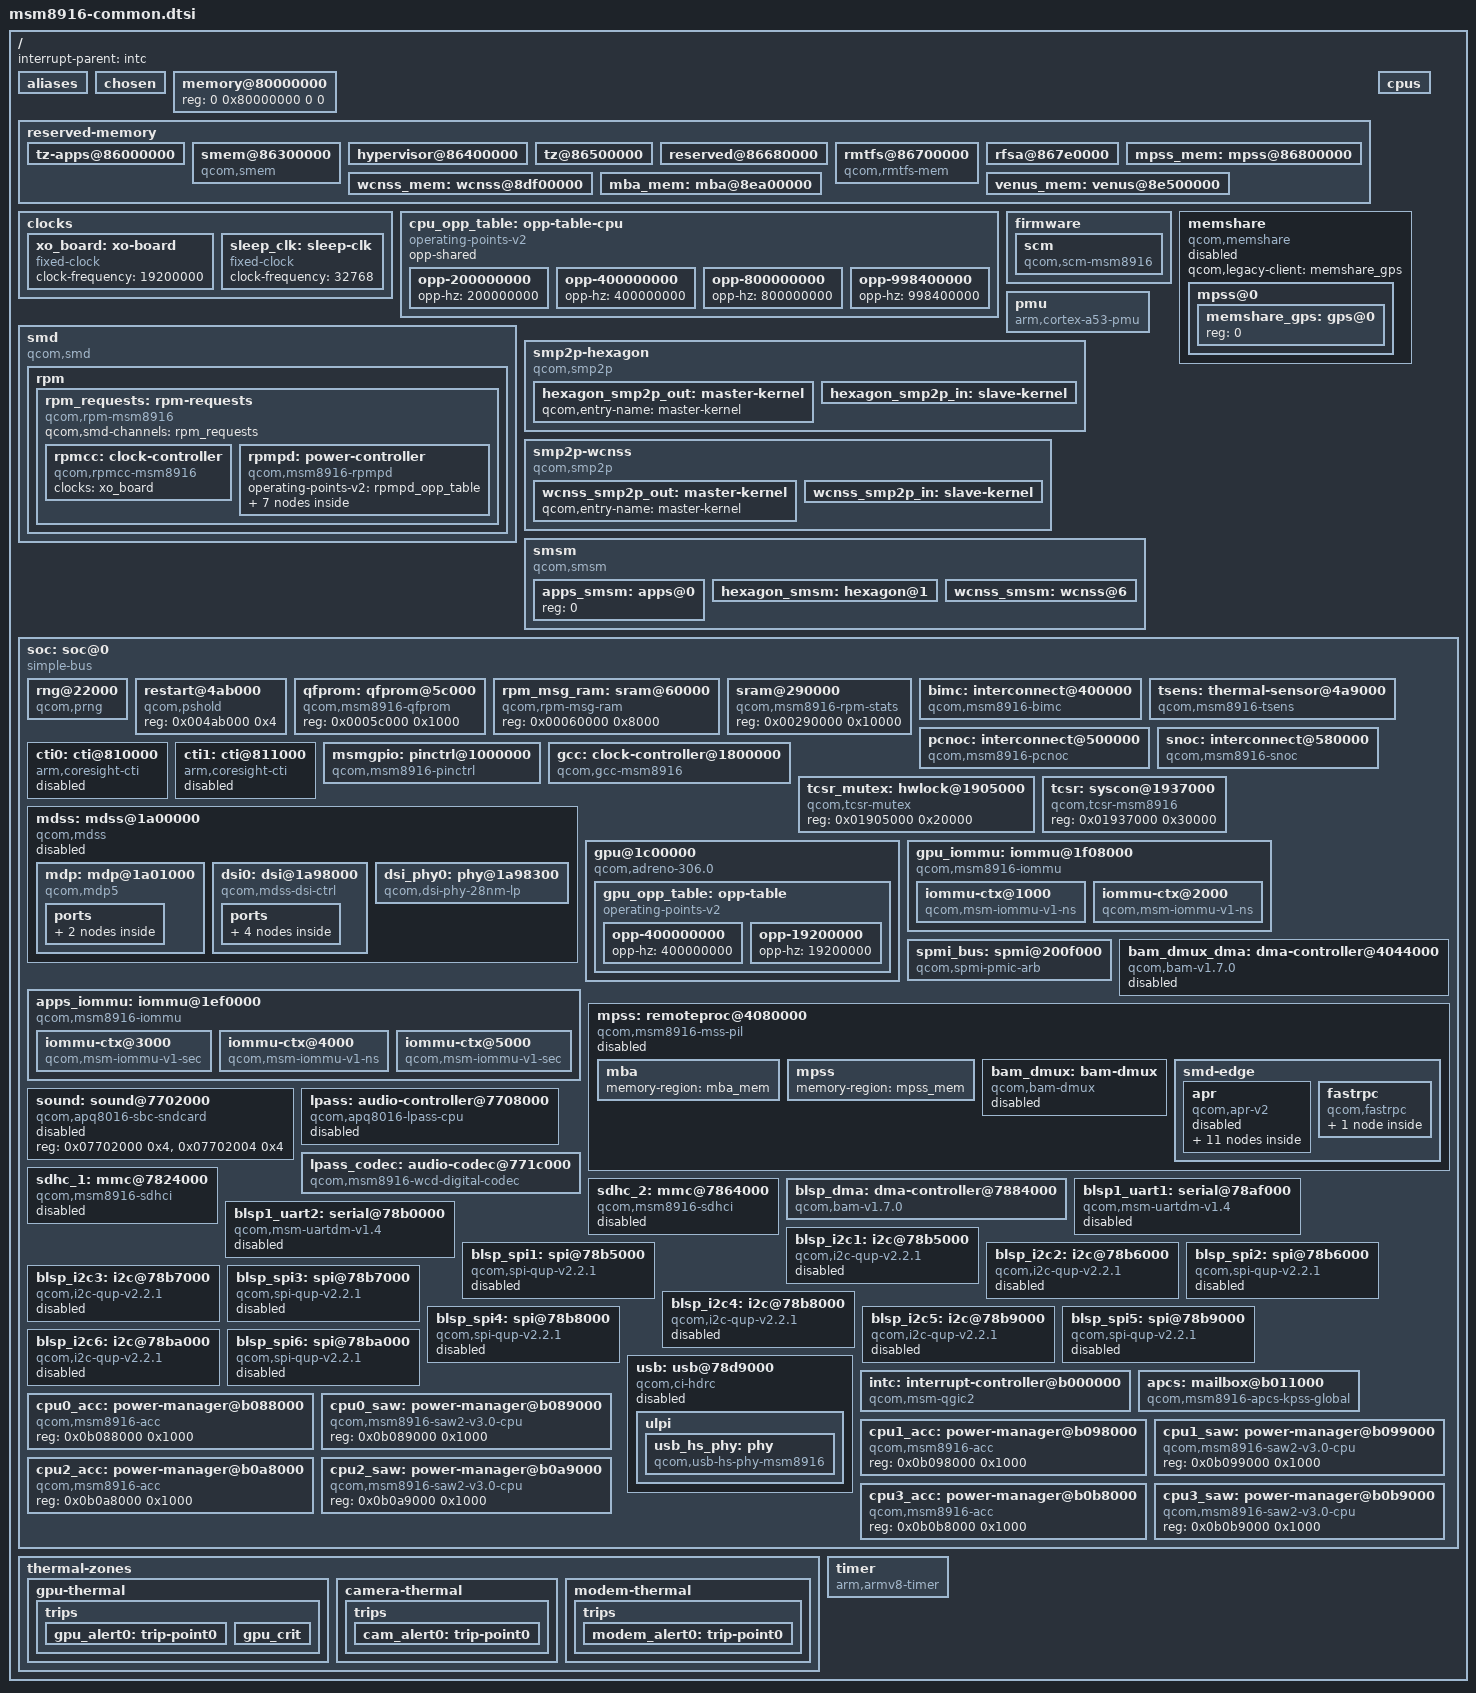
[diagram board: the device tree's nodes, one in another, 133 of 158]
// SPDX-License-Identifier: GPL-2.0-only
/*
 * Copyright (c) 2013-2015, The Linux Foundation. All rights reserved.
 */

#include <dt-bindings/clock/qcom,rpmcc.h>
#include <dt-bindings/interrupt-controller/arm-gic.h>
#include <dt-bindings/power/qcom-rpmpd.h>
#include <dt-bindings/soc/qcom,apr.h>
#include <dt-bindings/soc/qcom,memshare.h>
#include <dt-bindings/thermal/thermal.h>

/ {
	interrupt-parent = <&intc>;

	#address-cells = <2>;
	#size-cells = <2>;

	aliases {
		mmc0 = &sdhc_1; /* SDC1 eMMC slot */
		mmc1 = &sdhc_2; /* SDC2 SD card slot */
	};

	chosen { };

	memory@80000000 {
		device_type = "memory";
		/* We expect the bootloader to fill in the reg */
		reg = <0 0x80000000 0 0>;
	};

	reserved-memory {
		#address-cells = <2>;
		#size-cells = <2>;
		ranges;

		tz-apps@86000000 {
			reg = <0x0 0x86000000 0x0 0x300000>;
			no-map;
		};

		smem@86300000 {
			compatible = "qcom,smem";
			reg = <0x0 0x86300000 0x0 0x100000>;
			no-map;

			hwlocks = <&tcsr_mutex 3>;
			qcom,rpm-msg-ram = <&rpm_msg_ram>;
		};

		hypervisor@86400000 {
			reg = <0x0 0x86400000 0x0 0x100000>;
			no-map;
		};

		tz@86500000 {
			reg = <0x0 0x86500000 0x0 0x180000>;
			no-map;
		};

		reserved@86680000 {
			reg = <0x0 0x86680000 0x0 0x80000>;
			no-map;
		};

		rmtfs@86700000 {
			compatible = "qcom,rmtfs-mem";
			reg = <0x0 0x86700000 0x0 0xe0000>;
			no-map;

			qcom,client-id = <1>;
		};

		rfsa@867e0000 {
			reg = <0x0 0x867e0000 0x0 0x20000>;
			no-map;
		};

		mpss_mem: mpss@86800000 {
			reg = <0x0 0x86800000 0x0 0x2b00000>;
			no-map;
		};

		wcnss_mem: wcnss@8df00000 {
			reg = <0x0 0x8df00000 0x0 0x600000>;
			no-map;
		};

		venus_mem: venus@8e500000 {
			reg = <0x0 0x8e500000 0x0 0x500000>;
			no-map;
		};

		mba_mem: mba@8ea00000 {
			reg = <0x0 0x8ea00000 0x0 0x100000>;
			no-map;
		};
	};

	clocks {
		xo_board: xo-board {
			compatible = "fixed-clock";
			#clock-cells = <0>;
			clock-frequency = <19200000>;
		};

		sleep_clk: sleep-clk {
			compatible = "fixed-clock";
			#clock-cells = <0>;
			clock-frequency = <32768>;
		};
	};

	cpus { };

	cpu_opp_table: opp-table-cpu {
		compatible = "operating-points-v2";
		opp-shared;

		opp-200000000 {
			opp-hz = /bits/ 64 <200000000>;
		};
		opp-400000000 {
			opp-hz = /bits/ 64 <400000000>;
		};
		opp-800000000 {
			opp-hz = /bits/ 64 <800000000>;
		};
		opp-998400000 {
			opp-hz = /bits/ 64 <998400000>;
		};
	};

	firmware {
		scm: scm {
			compatible = "qcom,scm-msm8916", "qcom,scm";
			clocks = <&gcc GCC_CRYPTO_CLK>,
				 <&gcc GCC_CRYPTO_AXI_CLK>,
				 <&gcc GCC_CRYPTO_AHB_CLK>;
			clock-names = "core", "bus", "iface";
			#reset-cells = <1>;

			qcom,dload-mode = <&tcsr 0x6100>;
		};
	};

	memshare: memshare {
		compatible = "qcom,memshare";
		qcom,legacy-client = <&memshare_gps>;

		status = "disabled";

		#address-cells = <1>;
		#size-cells = <0>;

		mpss@0 {
			reg = <MEMSHARE_PROC_MPSS_V01>;
			qcom,qrtr-node = <0>;

			#address-cells = <1>;
			#size-cells = <0>;

			memshare_gps: gps@0 {
				reg = <0>;
			};
		};
	};

	pmu {
		compatible = "arm,cortex-a53-pmu";
		interrupts = <GIC_PPI 7 (GIC_CPU_MASK_SIMPLE(4) | IRQ_TYPE_LEVEL_HIGH)>;
	};

	smd {
		compatible = "qcom,smd";

		rpm {
			interrupts = <GIC_SPI 168 IRQ_TYPE_EDGE_RISING>;
			qcom,ipc = <&apcs 8 0>;
			qcom,smd-edge = <15>;

			rpm_requests: rpm-requests {
				compatible = "qcom,rpm-msm8916";
				qcom,smd-channels = "rpm_requests";

				rpmcc: clock-controller {
					compatible = "qcom,rpmcc-msm8916", "qcom,rpmcc";
					#clock-cells = <1>;
					clocks = <&xo_board>;
					clock-names = "xo";
				};

				rpmpd: power-controller {
					compatible = "qcom,msm8916-rpmpd";
					#power-domain-cells = <1>;
					operating-points-v2 = <&rpmpd_opp_table>;

					rpmpd_opp_table: opp-table {
						compatible = "operating-points-v2";

						rpmpd_opp_ret: opp1 {
							opp-level = <1>;
						};
						rpmpd_opp_svs_krait: opp2 {
							opp-level = <2>;
						};
						rpmpd_opp_svs_soc: opp3 {
							opp-level = <3>;
						};
						rpmpd_opp_nom: opp4 {
							opp-level = <4>;
						};
						rpmpd_opp_turbo: opp5 {
							opp-level = <5>;
						};
						rpmpd_opp_super_turbo: opp6 {
							opp-level = <6>;
						};
					};
				};
			};
		};
	};

	smp2p-hexagon {
		compatible = "qcom,smp2p";
		qcom,smem = <435>, <428>;

		interrupts = <GIC_SPI 27 IRQ_TYPE_EDGE_RISING>;

		qcom,ipc = <&apcs 8 14>;

		qcom,local-pid = <0>;
		qcom,remote-pid = <1>;

		hexagon_smp2p_out: master-kernel {
			qcom,entry-name = "master-kernel";

			#qcom,smem-state-cells = <1>;
		};

		hexagon_smp2p_in: slave-kernel {
			qcom,entry-name = "slave-kernel";

			interrupt-controller;
			#interrupt-cells = <2>;
		};
	};

	smp2p-wcnss {
		compatible = "qcom,smp2p";
		qcom,smem = <451>, <431>;

		interrupts = <GIC_SPI 143 IRQ_TYPE_EDGE_RISING>;

		qcom,ipc = <&apcs 8 18>;

		qcom,local-pid = <0>;
		qcom,remote-pid = <4>;

		wcnss_smp2p_out: master-kernel {
			qcom,entry-name = "master-kernel";

			#qcom,smem-state-cells = <1>;
		};

		wcnss_smp2p_in: slave-kernel {
			qcom,entry-name = "slave-kernel";

			interrupt-controller;
			#interrupt-cells = <2>;
		};
	};

	smsm {
		compatible = "qcom,smsm";

		#address-cells = <1>;
		#size-cells = <0>;

		qcom,ipc-1 = <&apcs 8 13>;
		qcom,ipc-3 = <&apcs 8 19>;

		apps_smsm: apps@0 {
			reg = <0>;

			#qcom,smem-state-cells = <1>;
		};

		hexagon_smsm: hexagon@1 {
			reg = <1>;
			interrupts = <GIC_SPI 26 IRQ_TYPE_EDGE_RISING>;

			interrupt-controller;
			#interrupt-cells = <2>;
		};

		wcnss_smsm: wcnss@6 {
			reg = <6>;
			interrupts = <GIC_SPI 144 IRQ_TYPE_EDGE_RISING>;

			interrupt-controller;
			#interrupt-cells = <2>;
		};
	};

	soc: soc@0 {
		#address-cells = <1>;
		#size-cells = <1>;
		ranges = <0 0 0 0xffffffff>;
		compatible = "simple-bus";

		rng@22000 {
			compatible = "qcom,prng";
			reg = <0x00022000 0x200>;
			clocks = <&gcc GCC_PRNG_AHB_CLK>;
			clock-names = "core";
		};

		restart@4ab000 {
			compatible = "qcom,pshold";
			reg = <0x004ab000 0x4>;
		};

		qfprom: qfprom@5c000 {
			compatible = "qcom,msm8916-qfprom", "qcom,qfprom";
			reg = <0x0005c000 0x1000>;
			#address-cells = <1>;
			#size-cells = <1>;
		};

		rpm_msg_ram: sram@60000 {
			compatible = "qcom,rpm-msg-ram";
			reg = <0x00060000 0x8000>;
		};

		sram@290000 {
			compatible = "qcom,msm8916-rpm-stats";
			reg = <0x00290000 0x10000>;
		};

		bimc: interconnect@400000 {
			compatible = "qcom,msm8916-bimc";
			reg = <0x00400000 0x62000>;
			#interconnect-cells = <1>;
			clock-names = "bus", "bus_a";
			clocks = <&rpmcc RPM_SMD_BIMC_CLK>,
				 <&rpmcc RPM_SMD_BIMC_A_CLK>;
		};

		tsens: thermal-sensor@4a9000 {
			compatible = "qcom,msm8916-tsens", "qcom,tsens-v0_1";
			reg = <0x004a9000 0x1000>, /* TM */
			      <0x004a8000 0x1000>; /* SROT */
			nvmem-cells = <&tsens_caldata>, <&tsens_calsel>;
			nvmem-cell-names = "calib", "calib_sel";
			#qcom,sensors = <5>;
			interrupts = <GIC_SPI 184 IRQ_TYPE_LEVEL_HIGH>;
			interrupt-names = "uplow";
			#thermal-sensor-cells = <1>;
		};

		pcnoc: interconnect@500000 {
			compatible = "qcom,msm8916-pcnoc";
			reg = <0x00500000 0x11000>;
			#interconnect-cells = <1>;
			clock-names = "bus", "bus_a";
			clocks = <&rpmcc RPM_SMD_PCNOC_CLK>,
				 <&rpmcc RPM_SMD_PCNOC_A_CLK>;
		};

		snoc: interconnect@580000 {
			compatible = "qcom,msm8916-snoc";
			reg = <0x00580000 0x14000>;
			#interconnect-cells = <1>;
			clock-names = "bus", "bus_a";
			clocks = <&rpmcc RPM_SMD_SNOC_CLK>,
				 <&rpmcc RPM_SMD_SNOC_A_CLK>;
		};

		/* System CTIs */
		/* CTI 0 - TMC connections */
		cti0: cti@810000 {
			compatible = "arm,coresight-cti", "arm,primecell";
			reg = <0x00810000 0x1000>;

			clocks = <&rpmcc RPM_QDSS_CLK>;
			clock-names = "apb_pclk";

			status = "disabled";
		};

		/* CTI 1 - TPIU connections */
		cti1: cti@811000 {
			compatible = "arm,coresight-cti", "arm,primecell";
			reg = <0x00811000 0x1000>;

			clocks = <&rpmcc RPM_QDSS_CLK>;
			clock-names = "apb_pclk";

			status = "disabled";
		};

		msmgpio: pinctrl@1000000 {
			compatible = "qcom,msm8916-pinctrl";
			reg = <0x01000000 0x300000>;
			interrupts = <GIC_SPI 208 IRQ_TYPE_LEVEL_HIGH>;
			gpio-controller;
			gpio-ranges = <&msmgpio 0 0 122>;
			#gpio-cells = <2>;
			interrupt-controller;
			#interrupt-cells = <2>;
		};

		gcc: clock-controller@1800000 {
			compatible = "qcom,gcc-msm8916";
			#clock-cells = <1>;
			#reset-cells = <1>;
			#power-domain-cells = <1>;
			reg = <0x01800000 0x80000>;
			clocks = <&xo_board>,
				 <&sleep_clk>,
				 <&dsi_phy0 1>,
				 <&dsi_phy0 0>,
				 <0>,
				 <0>,
				 <0>;
			clock-names = "xo",
				      "sleep_clk",
				      "dsi0pll",
				      "dsi0pllbyte",
				      "ext_mclk",
				      "ext_pri_i2s",
				      "ext_sec_i2s";
		};

		tcsr_mutex: hwlock@1905000 {
			compatible = "qcom,tcsr-mutex";
			reg = <0x01905000 0x20000>;
			#hwlock-cells = <1>;
		};

		tcsr: syscon@1937000 {
			compatible = "qcom,tcsr-msm8916", "syscon";
			reg = <0x01937000 0x30000>;
		};

		mdss: mdss@1a00000 {
			status = "disabled";
			compatible = "qcom,mdss";
			reg = <0x01a00000 0x1000>,
			      <0x01ac8000 0x3000>;
			reg-names = "mdss_phys", "vbif_phys";

			power-domains = <&gcc MDSS_GDSC>;

			clocks = <&gcc GCC_MDSS_AHB_CLK>,
				 <&gcc GCC_MDSS_AXI_CLK>,
				 <&gcc GCC_MDSS_VSYNC_CLK>;
			clock-names = "iface",
				      "bus",
				      "vsync";

			interrupts = <GIC_SPI 72 IRQ_TYPE_LEVEL_HIGH>;

			interrupt-controller;
			#interrupt-cells = <1>;

			#address-cells = <1>;
			#size-cells = <1>;
			ranges;

			mdp: mdp@1a01000 {
				compatible = "qcom,mdp5";
				reg = <0x01a01000 0x89000>;
				reg-names = "mdp_phys";

				interrupt-parent = <&mdss>;
				interrupts = <0>;

				clocks = <&gcc GCC_MDSS_AHB_CLK>,
					 <&gcc GCC_MDSS_AXI_CLK>,
					 <&gcc GCC_MDSS_MDP_CLK>,
					 <&gcc GCC_MDSS_VSYNC_CLK>;
				clock-names = "iface",
					      "bus",
					      "core",
					      "vsync";

				iommus = <&apps_iommu 4>;

				ports {
					#address-cells = <1>;
					#size-cells = <0>;

					port@0 {
						reg = <0>;
						mdp5_intf1_out: endpoint {
							remote-endpoint = <&dsi0_in>;
						};
					};
				};
			};

			dsi0: dsi@1a98000 {
				compatible = "qcom,mdss-dsi-ctrl";
				reg = <0x01a98000 0x25c>;
				reg-names = "dsi_ctrl";

				interrupt-parent = <&mdss>;
				interrupts = <4>;

				assigned-clocks = <&gcc BYTE0_CLK_SRC>,
						  <&gcc PCLK0_CLK_SRC>;
				assigned-clock-parents = <&dsi_phy0 0>,
							 <&dsi_phy0 1>;

				clocks = <&gcc GCC_MDSS_MDP_CLK>,
					 <&gcc GCC_MDSS_AHB_CLK>,
					 <&gcc GCC_MDSS_AXI_CLK>,
					 <&gcc GCC_MDSS_BYTE0_CLK>,
					 <&gcc GCC_MDSS_PCLK0_CLK>,
					 <&gcc GCC_MDSS_ESC0_CLK>;
				clock-names = "mdp_core",
					      "iface",
					      "bus",
					      "byte",
					      "pixel",
					      "core";
				phys = <&dsi_phy0>;

				#address-cells = <1>;
				#size-cells = <0>;

				ports {
					#address-cells = <1>;
					#size-cells = <0>;

					port@0 {
						reg = <0>;
						dsi0_in: endpoint {
							remote-endpoint = <&mdp5_intf1_out>;
						};
					};

					port@1 {
						reg = <1>;
						dsi0_out: endpoint {
						};
					};
				};
			};

			dsi_phy0: phy@1a98300 {
				compatible = "qcom,dsi-phy-28nm-lp";
				reg = <0x01a98300 0xd4>,
				      <0x01a98500 0x280>,
				      <0x01a98780 0x30>;
				reg-names = "dsi_pll",
					    "dsi_phy",
					    "dsi_phy_regulator";

				#clock-cells = <1>;
				#phy-cells = <0>;

				clocks = <&gcc GCC_MDSS_AHB_CLK>,
					 <&xo_board>;
				clock-names = "iface", "ref";
			};
		};

		gpu@1c00000 {
			compatible = "qcom,adreno-306.0", "qcom,adreno";
			reg = <0x01c00000 0x20000>;
			reg-names = "kgsl_3d0_reg_memory";
			interrupts = <GIC_SPI 33 IRQ_TYPE_LEVEL_HIGH>;
			interrupt-names = "kgsl_3d0_irq";
			clock-names =
			    "core",
			    "iface",
			    "mem",
			    "mem_iface",
			    "alt_mem_iface",
			    "gfx3d";
			clocks =
			    <&gcc GCC_OXILI_GFX3D_CLK>,
			    <&gcc GCC_OXILI_AHB_CLK>,
			    <&gcc GCC_OXILI_GMEM_CLK>,
			    <&gcc GCC_BIMC_GFX_CLK>,
			    <&gcc GCC_BIMC_GPU_CLK>,
			    <&gcc GFX3D_CLK_SRC>;
			power-domains = <&gcc OXILI_GDSC>;
			operating-points-v2 = <&gpu_opp_table>;
			iommus = <&gpu_iommu 1>, <&gpu_iommu 2>;

			gpu_opp_table: opp-table {
				compatible = "operating-points-v2";

				opp-400000000 {
					opp-hz = /bits/ 64 <400000000>;
				};
				opp-19200000 {
					opp-hz = /bits/ 64 <19200000>;
				};
			};
		};

		apps_iommu: iommu@1ef0000 {
			#address-cells = <1>;
			#size-cells = <1>;
			#iommu-cells = <1>;
			compatible = "qcom,msm8916-iommu", "qcom,msm-iommu-v1";
			ranges = <0 0x01e20000 0x40000>;
			reg = <0x01ef0000 0x3000>;
			clocks = <&gcc GCC_SMMU_CFG_CLK>,
				 <&gcc GCC_APSS_TCU_CLK>;
			clock-names = "iface", "bus";
			qcom,iommu-secure-id = <17>;

			/* VFE */
			iommu-ctx@3000 {
				compatible = "qcom,msm-iommu-v1-sec";
				reg = <0x3000 0x1000>;
				interrupts = <GIC_SPI 70 IRQ_TYPE_LEVEL_HIGH>;
			};

			/* MDP_0 */
			iommu-ctx@4000 {
				compatible = "qcom,msm-iommu-v1-ns";
				reg = <0x4000 0x1000>;
				interrupts = <GIC_SPI 70 IRQ_TYPE_LEVEL_HIGH>;
			};

			/* VENUS_NS */
			iommu-ctx@5000 {
				compatible = "qcom,msm-iommu-v1-sec";
				reg = <0x5000 0x1000>;
				interrupts = <GIC_SPI 70 IRQ_TYPE_LEVEL_HIGH>;
			};
		};

		gpu_iommu: iommu@1f08000 {
			#address-cells = <1>;
			#size-cells = <1>;
			#iommu-cells = <1>;
			compatible = "qcom,msm8916-iommu", "qcom,msm-iommu-v1";
			ranges = <0 0x01f08000 0x10000>;
			clocks = <&gcc GCC_SMMU_CFG_CLK>,
				 <&gcc GCC_GFX_TCU_CLK>;
			clock-names = "iface", "bus";
			qcom,iommu-secure-id = <18>;

			/* GFX3D_USER */
			iommu-ctx@1000 {
				compatible = "qcom,msm-iommu-v1-ns";
				reg = <0x1000 0x1000>;
				interrupts = <GIC_SPI 241 IRQ_TYPE_LEVEL_HIGH>;
			};

			/* GFX3D_PRIV */
			iommu-ctx@2000 {
				compatible = "qcom,msm-iommu-v1-ns";
				reg = <0x2000 0x1000>;
				interrupts = <GIC_SPI 242 IRQ_TYPE_LEVEL_HIGH>;
			};
		};

		spmi_bus: spmi@200f000 {
			compatible = "qcom,spmi-pmic-arb";
			reg = <0x0200f000 0x001000>,
			      <0x02400000 0x400000>,
			      <0x02c00000 0x400000>,
			      <0x03800000 0x200000>,
			      <0x0200a000 0x002100>;
			reg-names = "core", "chnls", "obsrvr", "intr", "cnfg";
			interrupt-names = "periph_irq";
			interrupts = <GIC_SPI 190 IRQ_TYPE_LEVEL_HIGH>;
			qcom,ee = <0>;
			qcom,channel = <0>;
			#address-cells = <2>;
			#size-cells = <0>;
			interrupt-controller;
			#interrupt-cells = <4>;
		};

		bam_dmux_dma: dma-controller@4044000 {
			compatible = "qcom,bam-v1.7.0";
			reg = <0x04044000 0x19000>;
			interrupts = <GIC_SPI 29 IRQ_TYPE_LEVEL_HIGH>;
			#dma-cells = <1>;
			qcom,ee = <0>;

			num-channels = <6>;
			qcom,num-ees = <1>;
			qcom,powered-remotely;

			status = "disabled";
		};

		mpss: remoteproc@4080000 {
			compatible = "qcom,msm8916-mss-pil";
			reg = <0x04080000 0x100>,
			      <0x04020000 0x040>;

			reg-names = "qdsp6", "rmb";

			interrupts-extended = <&intc GIC_SPI 24 IRQ_TYPE_EDGE_RISING>,
					      <&hexagon_smp2p_in 0 IRQ_TYPE_EDGE_RISING>,
					      <&hexagon_smp2p_in 1 IRQ_TYPE_EDGE_RISING>,
					      <&hexagon_smp2p_in 2 IRQ_TYPE_EDGE_RISING>,
					      <&hexagon_smp2p_in 3 IRQ_TYPE_EDGE_RISING>;
			interrupt-names = "wdog", "fatal", "ready",
					  "handover", "stop-ack";

			power-domains = <&rpmpd MSM8916_VDDCX>,
					<&rpmpd MSM8916_VDDMX>;
			power-domain-names = "cx", "mx";

			clocks = <&gcc GCC_MSS_CFG_AHB_CLK>,
				 <&gcc GCC_MSS_Q6_BIMC_AXI_CLK>,
				 <&gcc GCC_BOOT_ROM_AHB_CLK>,
				 <&xo_board>;
			clock-names = "iface", "bus", "mem", "xo";

			qcom,smem-states = <&hexagon_smp2p_out 0>;
			qcom,smem-state-names = "stop";

			resets = <&scm 0>;
			reset-names = "mss_restart";

			qcom,halt-regs = <&tcsr 0x18000 0x19000 0x1a000>;

			status = "disabled";

			mba {
				memory-region = <&mba_mem>;
			};

			mpss {
				memory-region = <&mpss_mem>;
			};

			bam_dmux: bam-dmux {
				compatible = "qcom,bam-dmux";

				interrupt-parent = <&hexagon_smsm>;
				interrupts = <1 IRQ_TYPE_EDGE_BOTH>, <11 IRQ_TYPE_EDGE_BOTH>;
				interrupt-names = "pc", "pc-ack";

				qcom,smem-states = <&apps_smsm 1>, <&apps_smsm 11>;
				qcom,smem-state-names = "pc", "pc-ack";

				dmas = <&bam_dmux_dma 4>, <&bam_dmux_dma 5>;
				dma-names = "tx", "rx";

				status = "disabled";
			};

			smd-edge {
				interrupts = <GIC_SPI 25 IRQ_TYPE_EDGE_RISING>;

				qcom,smd-edge = <0>;
				qcom,ipc = <&apcs 8 12>;
				qcom,remote-pid = <1>;

				label = "hexagon";

				apr: apr {
					compatible = "qcom,apr-v2";
					qcom,smd-channels = "apr_audio_svc";
					qcom,apr-domain = <APR_DOMAIN_ADSP>;
					#address-cells = <1>;
					#size-cells = <0>;
					status = "disabled";

					apr-service@3 {
						reg = <APR_SVC_ADSP_CORE>;
						compatible = "qcom,q6core";
					};

					q6afe: apr-service@4 {
						compatible = "qcom,q6afe";
						reg = <APR_SVC_AFE>;
						q6afedai: dais {
							compatible = "qcom,q6afe-dais";
							#address-cells = <1>;
							#size-cells = <0>;
							#sound-dai-cells = <1>;
						};
					};

					q6asm: apr-service@7 {
						compatible = "qcom,q6asm";
						reg = <APR_SVC_ASM>;
						q6asmdai: dais {
							compatible = "qcom,q6asm-dais";
							#address-cells = <1>;
							#size-cells = <0>;
							#sound-dai-cells = <1>;
						};
					};

					q6adm: apr-service@8 {
						compatible = "qcom,q6adm";
						reg = <APR_SVC_ADM>;
						q6routing: routing {
							compatible = "qcom,q6adm-routing";
							#sound-dai-cells = <0>;
						};
					};

					q6mvm: apr-service@9 {
						compatible = "qcom,q6mvm";
						reg = <APR_SVC_ADSP_MVM>;

						q6voicedai: dais {
							compatible = "qcom,q6voice-dais";
							#sound-dai-cells = <0>;
						};
					};

					q6cvs: apr-service@a {
						compatible = "qcom,q6cvs";
						reg = <APR_SVC_ADSP_CVS>;
					};

					q6cvp: apr-service@b {
						compatible = "qcom,q6cvp";
						reg = <APR_SVC_ADSP_CVP>;
					};
				};

				fastrpc {
					compatible = "qcom,fastrpc";
					qcom,smd-channels = "fastrpcsmd-apps-dsp";
					label = "adsp";
					qcom,non-secure-domain;

					#address-cells = <1>;
					#size-cells = <0>;

					cb@1 {
						compatible = "qcom,fastrpc-compute-cb";
						reg = <1>;
					};
				};
			};
		};

		sound: sound@7702000 {
			status = "disabled";
			compatible = "qcom,apq8016-sbc-sndcard";
			reg = <0x07702000 0x4>, <0x07702004 0x4>;
			reg-names = "mic-iomux", "spkr-iomux";
		};

		lpass: audio-controller@7708000 {
			status = "disabled";
			compatible = "qcom,apq8016-lpass-cpu";

			/*
			 * Note: Unlike the name would suggest, the SEC_I2S_CLK
			 * is actually only used by Tertiary MI2S while
			 * Primary/Secondary MI2S both use the PRI_I2S_CLK.
			 */
			clocks = <&gcc GCC_ULTAUDIO_AHBFABRIC_IXFABRIC_CLK>,
				 <&gcc GCC_ULTAUDIO_PCNOC_MPORT_CLK>,
				 <&gcc GCC_ULTAUDIO_PCNOC_SWAY_CLK>,
				 <&gcc GCC_ULTAUDIO_LPAIF_PRI_I2S_CLK>,
				 <&gcc GCC_ULTAUDIO_LPAIF_PRI_I2S_CLK>,
				 <&gcc GCC_ULTAUDIO_LPAIF_SEC_I2S_CLK>,
				 <&gcc GCC_ULTAUDIO_LPAIF_AUX_I2S_CLK>;

			clock-names = "ahbix-clk",
					"pcnoc-mport-clk",
					"pcnoc-sway-clk",
					"mi2s-bit-clk0",
					"mi2s-bit-clk1",
					"mi2s-bit-clk2",
					"mi2s-bit-clk3";
			#sound-dai-cells = <1>;

			interrupts = <GIC_SPI 160 IRQ_TYPE_LEVEL_HIGH>;
			interrupt-names = "lpass-irq-lpaif";
			reg = <0x07708000 0x10000>;
			reg-names = "lpass-lpaif";

			#address-cells = <1>;
			#size-cells = <0>;
		};

		lpass_codec: audio-codec@771c000 {
			compatible = "qcom,msm8916-wcd-digital-codec";
			reg = <0x0771c000 0x400>;
			clocks = <&gcc GCC_ULTAUDIO_AHBFABRIC_IXFABRIC_CLK>,
				 <&gcc GCC_CODEC_DIGCODEC_CLK>;
			clock-names = "ahbix-clk", "mclk";
			#sound-dai-cells = <1>;
		};

		sdhc_1: mmc@7824000 {
			compatible = "qcom,msm8916-sdhci", "qcom,sdhci-msm-v4";
			reg = <0x07824900 0x11c>, <0x07824000 0x800>;
			reg-names = "hc", "core";

			interrupts = <GIC_SPI 123 IRQ_TYPE_LEVEL_HIGH>,
				     <GIC_SPI 138 IRQ_TYPE_LEVEL_HIGH>;
			interrupt-names = "hc_irq", "pwr_irq";
			clocks = <&gcc GCC_SDCC1_AHB_CLK>,
				 <&gcc GCC_SDCC1_APPS_CLK>,
				 <&xo_board>;
			clock-names = "iface", "core", "xo";
			mmc-ddr-1_8v;
			bus-width = <8>;
			non-removable;
			status = "disabled";
		};

		sdhc_2: mmc@7864000 {
			compatible = "qcom,msm8916-sdhci", "qcom,sdhci-msm-v4";
			reg = <0x07864900 0x11c>, <0x07864000 0x800>;
			reg-names = "hc", "core";

			interrupts = <GIC_SPI 125 IRQ_TYPE_LEVEL_HIGH>,
				     <GIC_SPI 221 IRQ_TYPE_LEVEL_HIGH>;
			interrupt-names = "hc_irq", "pwr_irq";
			clocks = <&gcc GCC_SDCC2_AHB_CLK>,
				 <&gcc GCC_SDCC2_APPS_CLK>,
				 <&xo_board>;
			clock-names = "iface", "core", "xo";
			bus-width = <4>;
			status = "disabled";
		};

		blsp_dma: dma-controller@7884000 {
			compatible = "qcom,bam-v1.7.0";
			reg = <0x07884000 0x23000>;
			interrupts = <GIC_SPI 238 IRQ_TYPE_LEVEL_HIGH>;
			clocks = <&gcc GCC_BLSP1_AHB_CLK>;
			clock-names = "bam_clk";
			#dma-cells = <1>;
			qcom,ee = <0>;
		};

		blsp1_uart1: serial@78af000 {
			compatible = "qcom,msm-uartdm-v1.4", "qcom,msm-uartdm";
			reg = <0x078af000 0x200>;
			interrupts = <GIC_SPI 107 IRQ_TYPE_LEVEL_HIGH>;
			clocks = <&gcc GCC_BLSP1_UART1_APPS_CLK>, <&gcc GCC_BLSP1_AHB_CLK>;
			clock-names = "core", "iface";
			dmas = <&blsp_dma 0>, <&blsp_dma 1>;
			dma-names = "tx", "rx";
			pinctrl-0 = <&blsp1_uart1_default>;
			pinctrl-1 = <&blsp1_uart1_sleep>;
			pinctrl-names = "default", "sleep";
			status = "disabled";
		};

		blsp1_uart2: serial@78b0000 {
			compatible = "qcom,msm-uartdm-v1.4", "qcom,msm-uartdm";
			reg = <0x078b0000 0x200>;
			interrupts = <GIC_SPI 108 IRQ_TYPE_LEVEL_HIGH>;
			clocks = <&gcc GCC_BLSP1_UART2_APPS_CLK>, <&gcc GCC_BLSP1_AHB_CLK>;
			clock-names = "core", "iface";
			dmas = <&blsp_dma 2>, <&blsp_dma 3>;
			dma-names = "tx", "rx";
			pinctrl-0 = <&blsp1_uart2_default>;
			pinctrl-1 = <&blsp1_uart2_sleep>;
			pinctrl-names = "default", "sleep";
			status = "disabled";
		};

		blsp_i2c1: i2c@78b5000 {
			compatible = "qcom,i2c-qup-v2.2.1";
			reg = <0x078b5000 0x500>;
			interrupts = <GIC_SPI 95 IRQ_TYPE_LEVEL_HIGH>;
			clocks = <&gcc GCC_BLSP1_QUP1_I2C_APPS_CLK>,
				 <&gcc GCC_BLSP1_AHB_CLK>;
			clock-names = "core", "iface";
			dmas = <&blsp_dma 4>, <&blsp_dma 5>;
			dma-names = "tx", "rx";
			pinctrl-0 = <&i2c1_default>;
			pinctrl-1 = <&i2c1_sleep>;
			pinctrl-names = "default", "sleep";
			#address-cells = <1>;
			#size-cells = <0>;
			status = "disabled";
		};

		blsp_spi1: spi@78b5000 {
			compatible = "qcom,spi-qup-v2.2.1";
			reg = <0x078b5000 0x500>;
			interrupts = <GIC_SPI 95 IRQ_TYPE_LEVEL_HIGH>;
			clocks = <&gcc GCC_BLSP1_QUP1_SPI_APPS_CLK>,
				 <&gcc GCC_BLSP1_AHB_CLK>;
			clock-names = "core", "iface";
			dmas = <&blsp_dma 4>, <&blsp_dma 5>;
			dma-names = "tx", "rx";
			pinctrl-0 = <&spi1_default>;
			pinctrl-1 = <&spi1_sleep>;
			pinctrl-names = "default", "sleep";
			#address-cells = <1>;
			#size-cells = <0>;
			status = "disabled";
		};

		blsp_i2c2: i2c@78b6000 {
			compatible = "qcom,i2c-qup-v2.2.1";
			reg = <0x078b6000 0x500>;
			interrupts = <GIC_SPI 96 IRQ_TYPE_LEVEL_HIGH>;
			clocks = <&gcc GCC_BLSP1_QUP2_I2C_APPS_CLK>,
				 <&gcc GCC_BLSP1_AHB_CLK>;
			clock-names = "core", "iface";
			dmas = <&blsp_dma 6>, <&blsp_dma 7>;
			dma-names = "tx", "rx";
			pinctrl-0 = <&i2c2_default>;
			pinctrl-1 = <&i2c2_sleep>;
			pinctrl-names = "default", "sleep";
			#address-cells = <1>;
			#size-cells = <0>;
			status = "disabled";
		};

		blsp_spi2: spi@78b6000 {
			compatible = "qcom,spi-qup-v2.2.1";
			reg = <0x078b6000 0x500>;
			interrupts = <GIC_SPI 96 IRQ_TYPE_LEVEL_HIGH>;
			clocks = <&gcc GCC_BLSP1_QUP2_SPI_APPS_CLK>,
				 <&gcc GCC_BLSP1_AHB_CLK>;
			clock-names = "core", "iface";
			dmas = <&blsp_dma 6>, <&blsp_dma 7>;
			dma-names = "tx", "rx";
			pinctrl-0 = <&spi2_default>;
			pinctrl-1 = <&spi2_sleep>;
			pinctrl-names = "default", "sleep";
			#address-cells = <1>;
			#size-cells = <0>;
			status = "disabled";
		};

		blsp_i2c3: i2c@78b7000 {
			compatible = "qcom,i2c-qup-v2.2.1";
			reg = <0x078b7000 0x500>;
			interrupts = <GIC_SPI 97 IRQ_TYPE_LEVEL_HIGH>;
			clocks = <&gcc GCC_BLSP1_QUP3_I2C_APPS_CLK>,
				 <&gcc GCC_BLSP1_AHB_CLK>;
			clock-names = "core", "iface";
			dmas = <&blsp_dma 8>, <&blsp_dma 9>;
			dma-names = "tx", "rx";
			pinctrl-0 = <&i2c3_default>;
			pinctrl-1 = <&i2c3_sleep>;
			pinctrl-names = "default", "sleep";
			#address-cells = <1>;
			#size-cells = <0>;
			status = "disabled";
		};

		blsp_spi3: spi@78b7000 {
			compatible = "qcom,spi-qup-v2.2.1";
			reg = <0x078b7000 0x500>;
			interrupts = <GIC_SPI 97 IRQ_TYPE_LEVEL_HIGH>;
			clocks = <&gcc GCC_BLSP1_QUP3_SPI_APPS_CLK>,
				 <&gcc GCC_BLSP1_AHB_CLK>;
			clock-names = "core", "iface";
			dmas = <&blsp_dma 8>, <&blsp_dma 9>;
			dma-names = "tx", "rx";
			pinctrl-0 = <&spi3_default>;
			pinctrl-1 = <&spi3_sleep>;
			pinctrl-names = "default", "sleep";
			#address-cells = <1>;
			#size-cells = <0>;
			status = "disabled";
		};

		blsp_i2c4: i2c@78b8000 {
			compatible = "qcom,i2c-qup-v2.2.1";
			reg = <0x078b8000 0x500>;
			interrupts = <GIC_SPI 98 IRQ_TYPE_LEVEL_HIGH>;
			clocks = <&gcc GCC_BLSP1_QUP4_I2C_APPS_CLK>,
				 <&gcc GCC_BLSP1_AHB_CLK>;
			clock-names = "core", "iface";
			dmas = <&blsp_dma 10>, <&blsp_dma 11>;
			dma-names = "tx", "rx";
			pinctrl-0 = <&i2c4_default>;
			pinctrl-1 = <&i2c4_sleep>;
			pinctrl-names = "default", "sleep";
			#address-cells = <1>;
			#size-cells = <0>;
			status = "disabled";
		};

		blsp_spi4: spi@78b8000 {
			compatible = "qcom,spi-qup-v2.2.1";
			reg = <0x078b8000 0x500>;
			interrupts = <GIC_SPI 98 IRQ_TYPE_LEVEL_HIGH>;
			clocks = <&gcc GCC_BLSP1_QUP4_SPI_APPS_CLK>,
				 <&gcc GCC_BLSP1_AHB_CLK>;
			clock-names = "core", "iface";
			dmas = <&blsp_dma 10>, <&blsp_dma 11>;
			dma-names = "tx", "rx";
			pinctrl-0 = <&spi4_default>;
			pinctrl-1 = <&spi4_sleep>;
			pinctrl-names = "default", "sleep";
			#address-cells = <1>;
			#size-cells = <0>;
			status = "disabled";
		};

		blsp_i2c5: i2c@78b9000 {
			compatible = "qcom,i2c-qup-v2.2.1";
			reg = <0x078b9000 0x500>;
			interrupts = <GIC_SPI 99 IRQ_TYPE_LEVEL_HIGH>;
			clocks = <&gcc GCC_BLSP1_QUP5_I2C_APPS_CLK>,
				 <&gcc GCC_BLSP1_AHB_CLK>;
			clock-names = "core", "iface";
			dmas = <&blsp_dma 12>, <&blsp_dma 13>;
			dma-names = "tx", "rx";
			pinctrl-0 = <&i2c5_default>;
			pinctrl-1 = <&i2c5_sleep>;
			pinctrl-names = "default", "sleep";
			#address-cells = <1>;
			#size-cells = <0>;
			status = "disabled";
		};

		blsp_spi5: spi@78b9000 {
			compatible = "qcom,spi-qup-v2.2.1";
			reg = <0x078b9000 0x500>;
			interrupts = <GIC_SPI 99 IRQ_TYPE_LEVEL_HIGH>;
			clocks = <&gcc GCC_BLSP1_QUP5_SPI_APPS_CLK>,
				 <&gcc GCC_BLSP1_AHB_CLK>;
			clock-names = "core", "iface";
			dmas = <&blsp_dma 12>, <&blsp_dma 13>;
			dma-names = "tx", "rx";
			pinctrl-0 = <&spi5_default>;
			pinctrl-1 = <&spi5_sleep>;
			pinctrl-names = "default", "sleep";
			#address-cells = <1>;
			#size-cells = <0>;
			status = "disabled";
		};

		blsp_i2c6: i2c@78ba000 {
			compatible = "qcom,i2c-qup-v2.2.1";
			reg = <0x078ba000 0x500>;
			interrupts = <GIC_SPI 100 IRQ_TYPE_LEVEL_HIGH>;
			clocks = <&gcc GCC_BLSP1_QUP6_I2C_APPS_CLK>,
				 <&gcc GCC_BLSP1_AHB_CLK>;
			clock-names = "core", "iface";
			dmas = <&blsp_dma 14>, <&blsp_dma 15>;
			dma-names = "tx", "rx";
			pinctrl-0 = <&i2c6_default>;
			pinctrl-1 = <&i2c6_sleep>;
			pinctrl-names = "default", "sleep";
			#address-cells = <1>;
			#size-cells = <0>;
			status = "disabled";
		};

		blsp_spi6: spi@78ba000 {
			compatible = "qcom,spi-qup-v2.2.1";
			reg = <0x078ba000 0x500>;
			interrupts = <GIC_SPI 100 IRQ_TYPE_LEVEL_HIGH>;
			clocks = <&gcc GCC_BLSP1_QUP6_SPI_APPS_CLK>,
				 <&gcc GCC_BLSP1_AHB_CLK>;
			clock-names = "core", "iface";
			dmas = <&blsp_dma 14>, <&blsp_dma 15>;
			dma-names = "tx", "rx";
			pinctrl-0 = <&spi6_default>;
			pinctrl-1 = <&spi6_sleep>;
			pinctrl-names = "default", "sleep";
			#address-cells = <1>;
			#size-cells = <0>;
			status = "disabled";
		};

		usb: usb@78d9000 {
			compatible = "qcom,ci-hdrc";
			reg = <0x078d9000 0x200>,
			      <0x078d9200 0x200>;
			interrupts = <GIC_SPI 134 IRQ_TYPE_LEVEL_HIGH>,
				     <GIC_SPI 140 IRQ_TYPE_LEVEL_HIGH>;
			clocks = <&gcc GCC_USB_HS_AHB_CLK>,
				 <&gcc GCC_USB_HS_SYSTEM_CLK>;
			clock-names = "iface", "core";
			assigned-clocks = <&gcc GCC_USB_HS_SYSTEM_CLK>;
			assigned-clock-rates = <80000000>;
			resets = <&gcc GCC_USB_HS_BCR>;
			reset-names = "core";
			phy_type = "ulpi";
			dr_mode = "otg";
			hnp-disable;
			srp-disable;
			adp-disable;
			ahb-burst-config = <0>;
			phy-names = "usb-phy";
			phys = <&usb_hs_phy>;
			status = "disabled";
			#reset-cells = <1>;

			ulpi {
				usb_hs_phy: phy {
					compatible = "qcom,usb-hs-phy-msm8916",
						     "qcom,usb-hs-phy";
					#phy-cells = <0>;
					clocks = <&xo_board>, <&gcc GCC_USB2A_PHY_SLEEP_CLK>;
					clock-names = "ref", "sleep";
					resets = <&gcc GCC_USB2A_PHY_BCR>, <&usb 0>;
					reset-names = "phy", "por";
					qcom,init-seq = /bits/ 8 <0x0 0x44>,
								 <0x1 0x6b>,
								 <0x2 0x24>,
								 <0x3 0x13>;
				};
			};
		};

		intc: interrupt-controller@b000000 {
			compatible = "qcom,msm-qgic2";
			interrupt-controller;
			#interrupt-cells = <3>;
			reg = <0x0b000000 0x1000>, <0x0b002000 0x2000>,
			      <0x0b001000 0x1000>, <0x0b004000 0x2000>;
			interrupts = <GIC_PPI 0 (GIC_CPU_MASK_SIMPLE(4) | IRQ_TYPE_LEVEL_HIGH)>;
		};

		apcs: mailbox@b011000 {
			compatible = "qcom,msm8916-apcs-kpss-global", "syscon";
			reg = <0x0b011000 0x1000>;
			#mbox-cells = <1>;
			clocks = <&a53pll>, <&gcc GPLL0_VOTE>;
			clock-names = "pll", "aux";
			#clock-cells = <0>;
		};

		cpu0_acc: power-manager@b088000 {
			compatible = "qcom,msm8916-acc";
			reg = <0x0b088000 0x1000>;
		};

		cpu0_saw: power-manager@b089000 {
			compatible = "qcom,msm8916-saw2-v3.0-cpu", "qcom,saw2";
			reg = <0x0b089000 0x1000>;
		};

		cpu1_acc: power-manager@b098000 {
			compatible = "qcom,msm8916-acc";
			reg = <0x0b098000 0x1000>;
		};

		cpu1_saw: power-manager@b099000 {
			compatible = "qcom,msm8916-saw2-v3.0-cpu", "qcom,saw2";
			reg = <0x0b099000 0x1000>;
		};

		cpu2_acc: power-manager@b0a8000 {
			compatible = "qcom,msm8916-acc";
			reg = <0x0b0a8000 0x1000>;
		};

		cpu2_saw: power-manager@b0a9000 {
			compatible = "qcom,msm8916-saw2-v3.0-cpu", "qcom,saw2";
			reg = <0x0b0a9000 0x1000>;
		};

		cpu3_acc: power-manager@b0b8000 {
			compatible = "qcom,msm8916-acc";
			reg = <0x0b0b8000 0x1000>;
		};

		cpu3_saw: power-manager@b0b9000 {
			compatible = "qcom,msm8916-saw2-v3.0-cpu", "qcom,saw2";
			reg = <0x0b0b9000 0x1000>;
		};
	};

	thermal-zones {
		gpu-thermal {
			polling-delay-passive = <250>;
			polling-delay = <1000>;

			thermal-sensors = <&tsens 2>;

			trips {
				gpu_alert0: trip-point0 {
					temperature = <75000>;
					hysteresis = <2000>;
					type = "passive";
				};
				gpu_crit: gpu_crit {
					temperature = <95000>;
					hysteresis = <2000>;
					type = "critical";
				};
			};
		};

		camera-thermal {
			polling-delay-passive = <250>;
			polling-delay = <1000>;

			thermal-sensors = <&tsens 1>;

			trips {
				cam_alert0: trip-point0 {
					temperature = <75000>;
					hysteresis = <2000>;
					type = "hot";
				};
			};
		};

		modem-thermal {
			polling-delay-passive = <250>;
			polling-delay = <1000>;

			thermal-sensors = <&tsens 0>;

			trips {
				modem_alert0: trip-point0 {
					temperature = <85000>;
					hysteresis = <2000>;
					type = "hot";
				};
			};
		};
	};

	timer {
		compatible = "arm,armv8-timer";
		interrupts = <GIC_PPI 2 (GIC_CPU_MASK_SIMPLE(4) | IRQ_TYPE_LEVEL_LOW)>,
			     <GIC_PPI 3 (GIC_CPU_MASK_SIMPLE(4) | IRQ_TYPE_LEVEL_LOW)>,
			     <GIC_PPI 4 (GIC_CPU_MASK_SIMPLE(4) | IRQ_TYPE_LEVEL_LOW)>,
			     <GIC_PPI 1 (GIC_CPU_MASK_SIMPLE(4) | IRQ_TYPE_LEVEL_LOW)>;
	};
};

#include "msm8916-pins.dtsi"
